# Q32M210 register map
File version: 1.0
Registers are 32-bit, read-write, no defined reset value unless marked. A register's access mark holds for its fields unless they carry their own. Offsets are from the block's base; [hi:lo] are bit positions; {n}, {i} and the like mark numbered series.

## Flash_Update_Control
Base 0x40000F04
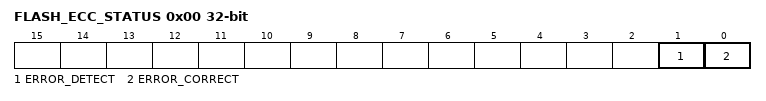
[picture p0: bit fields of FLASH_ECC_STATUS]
0x00 FLASH_ECC_STATUS — Flash Error-Correction Coding Status
  [1] ERROR_DETECT — An ECC error was detected, but not corrected
    0=ECC_ERROR_NOT_DETECTED (No ECC errors have been detected); 1=ECC_ERROR_DETECT_CLEAR (Clear the ECC error detect status bit); 1=ECC_ERROR_DETECTED (One or more ECC errors have been detected)
  [0] ERROR_CORRECT — An ECC error was detected and corrected
    0=ECC_ERROR_NOT_CORRECTED (No ECC errors have been corrected); 1=ECC_ERROR_CORRECT_CLEAR (Clear the ECC error correct status bit); 1=ECC_ERROR_CORRECTED (One or more ECC errors have been corrected)
0x10 FLASH_WRITE_LOCK
  [31:0] FLASH_WRITE_KEY — Write key to protect accidental flash writing to the main flash memory
    0xABCD4321=FLASH_WRITE_KEY (Key used to unlock writes to the flash)

## SYSTICK_Timer
Base 0xE000E010
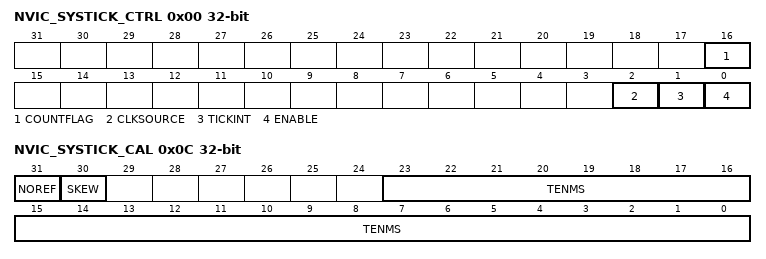
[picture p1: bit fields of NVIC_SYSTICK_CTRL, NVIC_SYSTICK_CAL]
0x00 NVIC_SYSTICK_CTRL — NVIC SYSTICK Control and Status Register
  [16] COUNTFLAG — Reads as 1 if SYSTICK counter has reached 0 since the last time the timer has reached 0. Clears to 0 on read.
    0=NVIC_COUNTFLAG_NOT_ZERO (SYSTICK counter has not reached zero since last read); 1=NVIC_COUNTFLAG_ZERO (SYSTICK counter has reached zero since last read)
  [2] CLKSOURCE — SYSTICK timer clock source
    0=NVIC_CLKSOURCE_EXTREF_CLK (Use external reference clock (STCLK)); 1=NVIC_CLKSOURCE_CORE_CLK (Use the core clock)
  [1] TICKINT — SYSTICK timer interrupt enable
    0=NVIC_TICKINT_DISABLE (Disable interrupt generation when SYSTICK timer reaches 0); 1=NVIC_TICKINT_ENABLE (Enable interrupt generation when SYSTICK timer reaches 0)
  [0] ENABLE — SYSTICK timer enable
    0=NVIC_SYSTICK_DISABLE (Disable SYSTICK timer); 1=NVIC_SYSTICK_ENABLE (Enable SYSTICK Timer)
0x04 NVIC_SYSTICK_RELOAD — NVIC SYSTICK Reload Value Register
  [23:0] COUNT — Counter reload value for the SYSTICK timer when it reaches 0
0x08 NVIC_SYSTICK_CURRENT — NVIC SYSTICK Current Value Register
  [23:0] COUNT — Current value of the SYSTICK counter value. Write to clear counter.
0x0C NVIC_SYSTICK_CAL — NVIC SYSTICK Calibration Register
  [31] NOREF — Indicates if a reference clock is available
    1=NVIC_SYSTICK_NOREF (No external reference clock available); 0=NVIC_SYSTICK_REF (External reference clock available)
  [30] SKEW — Indicates if calibration value is exactly 10 ms or not
    1=NVIC_SYSTICK_SKEW (Calibration value is not exactly 10 ms); 0=NVIC_SYSTICK_NOSKEW (Calibration value is exactly 10 ms)
  [23:0] TENMS — SYSTICK counter calibration value for 10 ms. A value of 0 means the calibration value is not available

## Debug_Controller
Base 0xE000EDF0
0x00 DEBUG_HALT_CTRL — Debug Halting Control and Status Register
  [25] S_RESET_ST — Core has been reset or is being rest. Bit is cleared on read.
  [24] S_RETIRE_ST
  [19] S_LOCKUP — Indicates if core is in lockup state
  [18] S_SLEEP — Indicates if core is in sleep mode
  [17] S_HALT — Indicates is core is halted
  [31:16] KEY — Debug key must be written to this field in order to write the rest of the register
    0xA05F=DEBUG_HALT_KEY (Key to unlock DEBUGHALT_CTRL register)
  [16] S_REGRDY — Indicates register read/write operation is completed
  [5] C_SNAPSTALL — Set to break a stalled memory access
  [3] C_MASKINTS — Mask interrupts while stepping
  [2] C_STEP — Single step the processor
  [1] C_HALT — Halt the processor
  [0] C_DEBUGEN — Enable halt mode debugging
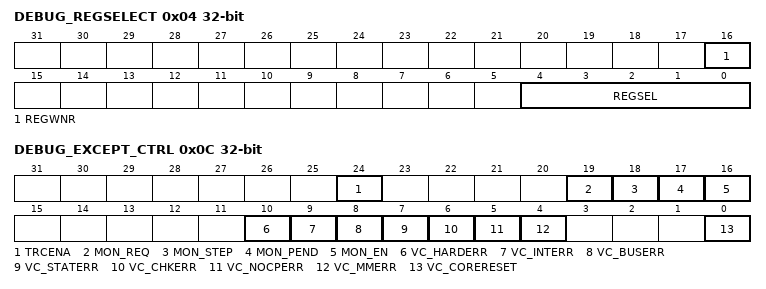
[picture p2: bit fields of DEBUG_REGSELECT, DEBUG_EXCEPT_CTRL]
0x04 DEBUG_REGSELECT — Debug Core Register Selector Register
  [16] REGWNR — Indicates direction of register transfer
    0=REGWNR_READ (Indicates register read); 1=REGWNR_WRITE (Indicates register write)
  [4:0] REGSEL — Indicates register to be accessed
    {v}=REGSEL_R{v} (Select R{v}) (v=0..15); 16=REGSEL_PSRFLGS (Select xPSR/flags); 17=REGSEL_MSP (Select main stack pointer); 18=REGSEL_PSP (Select process stack pointer); 20=REGSEL_SPECREG (Access other registers including control, FAULTMASK, BASEPRI and PRIMASK)
0x08 DEBUG_REGDATA — Debug Core Register Data Register
  [31:0] DEBUG_REGDATA — Register read/write data for debugging
0x0C DEBUG_EXCEPT_CTRL — Debug Exception and Monitor Control Register
  [24] TRCENA — Trace system enable
  [19] MON_REQ — Indicates that the debug monitor is caused by a manual pending request rather than a hardware event
  [18] MON_STEP — Single step the processor
  [17] MON_PEND — Pend the monitor exception request
    0=DEBUG_MON_CLRPEND (Clear the pending status of the debug monitor exception); 1=DEBUG_MON_SETPEND (Set pending status of the debug monitor exception)
  [16] MON_EN — Enable the debug monitor exception
    0=DEBUG_MON_DISABLE (Disable debug monitor exceptions); 1=DEBUG_MON_ENABLE (Enable debug monitor exceptions)
  [10] VC_HARDERR — Debug trap on hard faults
  [9] VC_INTERR — Debug trap on interrupt service errors
  [8] VC_BUSERR — Debug trap on bus faults
  [7] VC_STATERR — Debug trap on usage fault state errors
  [6] VC_CHKERR — Debug trap on fault-enabled checking errors (e.g. unaligned access, divide by zero, etc.)
  [5] VC_NOCPERR — Debug trap on usage fault no coprocessor errors
  [4] VC_MMERR — Debug trap on memory management fault
  [0] VC_CORERESET — Debug trap on core reset
